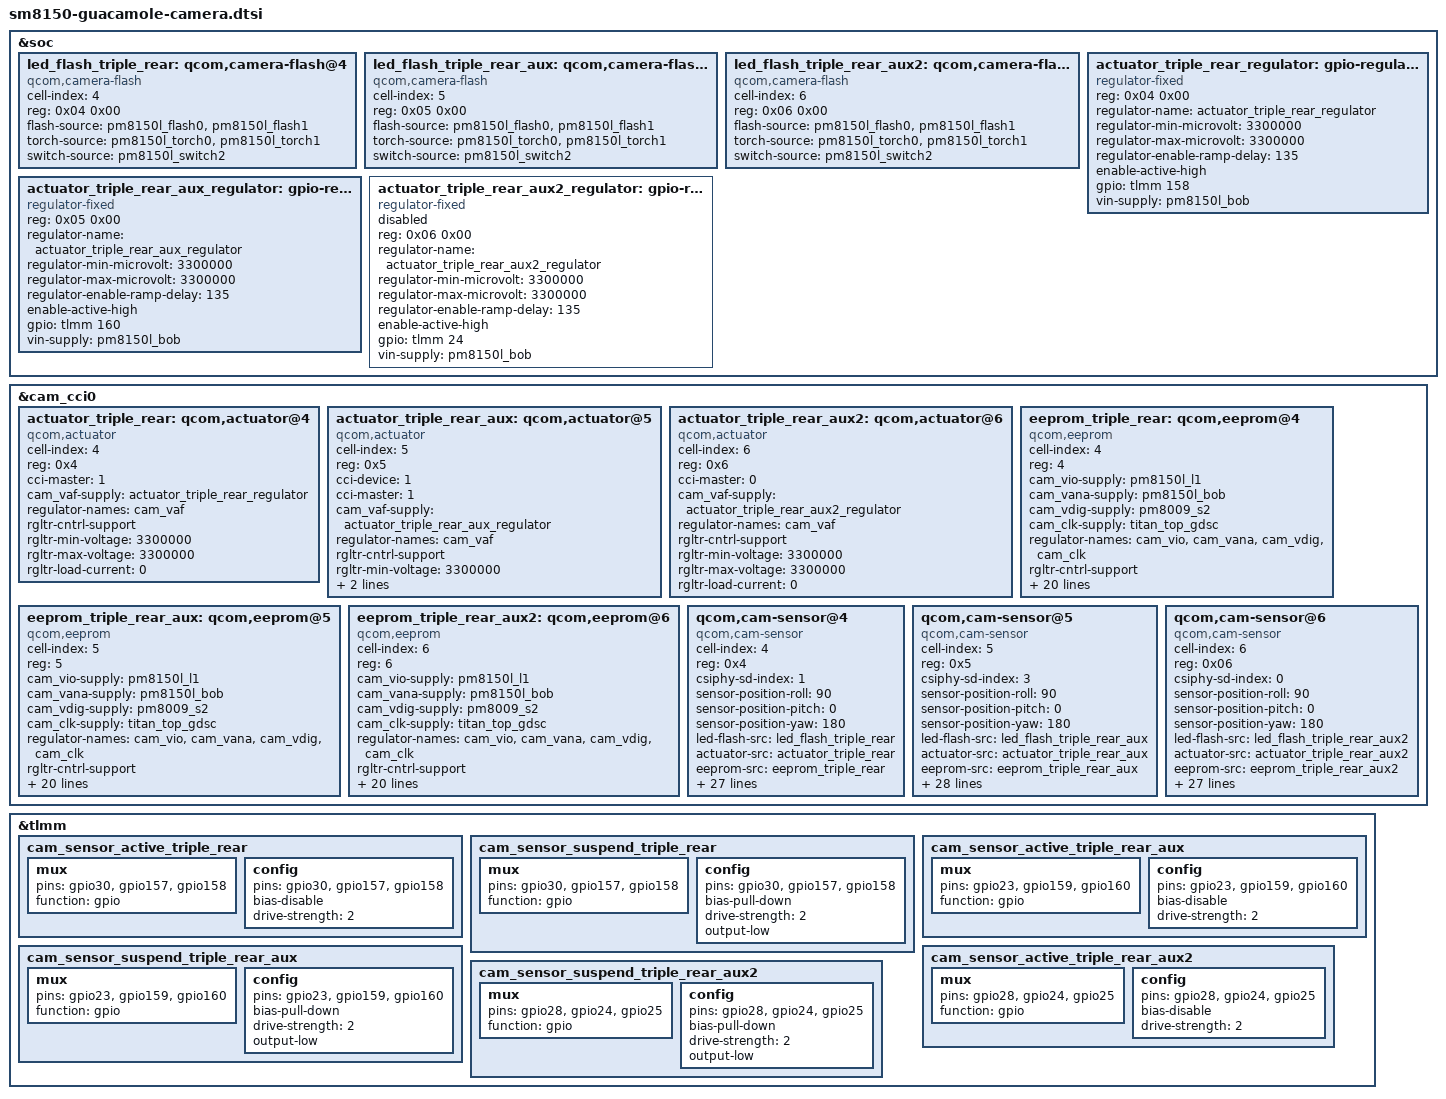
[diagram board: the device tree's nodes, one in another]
/*
 * Copyright (c) 2018, The Linux Foundation. All rights reserved.
 *
 * This program is free software; you can redistribute it and/or modify
 * it under the terms of the GNU General Public License version 2 and
 * only version 2 as published by the Free Software Foundation.
 *
 * This program is distributed in the hope that it will be useful,
 * but WITHOUT ANY WARRANTY; without even the implied warranty of
 * MERCHANTABILITY or FITNESS FOR A PARTICULAR PURPOSE.  See the
 * GNU General Public License for more details.
 */

&soc {
	led_flash_triple_rear: qcom,camera-flash@4 {
		cell-index = <4>;
		reg = <0x04 0x00>;
		compatible = "qcom,camera-flash";
		flash-source = <&pm8150l_flash0 &pm8150l_flash1>;
		torch-source = <&pm8150l_torch0 &pm8150l_torch1>;
		switch-source = <&pm8150l_switch2>;
		status = "ok";
	};

	led_flash_triple_rear_aux: qcom,camera-flash@5 {
		cell-index = <5>;
		reg = <0x05 0x00>;
		compatible = "qcom,camera-flash";
		flash-source = <&pm8150l_flash0 &pm8150l_flash1>;
		torch-source = <&pm8150l_torch0 &pm8150l_torch1>;
		switch-source = <&pm8150l_switch2>;
		status = "ok";
	};

	led_flash_triple_rear_aux2: qcom,camera-flash@6 {
		cell-index = <6>;
		reg = <0x06 0x00>;
		compatible = "qcom,camera-flash";
		flash-source = <&pm8150l_flash0 &pm8150l_flash1>;
		torch-source = <&pm8150l_torch0 &pm8150l_torch1>;
		switch-source = <&pm8150l_switch2>;
		status = "ok";
	};

	actuator_triple_rear_regulator: gpio-regulator@4 {
		compatible = "regulator-fixed";
		reg = <0x04 0x00>;
		regulator-name = "actuator_triple_rear_regulator";
		regulator-min-microvolt = <3300000>;
		regulator-max-microvolt = <3300000>;
		regulator-enable-ramp-delay = <135>;
		enable-active-high;
		gpio = <&tlmm 158 0>;
		vin-supply = <&pm8150l_bob>;
	};

	actuator_triple_rear_aux_regulator: gpio-regulator@5 {
		compatible = "regulator-fixed";
		reg = <0x05 0x00>;
		regulator-name = "actuator_triple_rear_aux_regulator";
		regulator-min-microvolt = <3300000>;
		regulator-max-microvolt = <3300000>;
		regulator-enable-ramp-delay = <135>;
		enable-active-high;
		gpio = <&tlmm 160 0>;
		vin-supply = <&pm8150l_bob>;
	};

	actuator_triple_rear_aux2_regulator: gpio-regulator@6 {
		compatible = "regulator-fixed";
		status = "disable";
		reg = <0x06 0x00>;
		regulator-name = "actuator_triple_rear_aux2_regulator";
		regulator-min-microvolt = <3300000>;
		regulator-max-microvolt = <3300000>;
		regulator-enable-ramp-delay = <135>;
		enable-active-high;
		gpio = <&tlmm 24 0>;
		vin-supply = <&pm8150l_bob>;
	};
};

&cam_cci0 {
	actuator_triple_rear: qcom,actuator@4 {
		cell-index = <4>;
		reg = <0x4>;
		compatible = "qcom,actuator";
		cci-master = <1>;
		cam_vaf-supply = <&actuator_triple_rear_regulator>;
		regulator-names = "cam_vaf";
		rgltr-cntrl-support;
		rgltr-min-voltage = <3300000>;
		rgltr-max-voltage = <3300000>;
		rgltr-load-current = <0>;
	};

	actuator_triple_rear_aux: qcom,actuator@5 {
		cell-index = <5>;
		reg = <0x5>;
		compatible = "qcom,actuator";
		cci-device = <1>;
		cci-master = <1>;
		cam_vaf-supply = <&actuator_triple_rear_aux_regulator>;
		regulator-names = "cam_vaf";
		rgltr-cntrl-support;
		rgltr-min-voltage = <3300000>;
		rgltr-max-voltage = <3300000>;
		rgltr-load-current = <0>;
	};

	actuator_triple_rear_aux2: qcom,actuator@6 {
		cell-index = <6>;
		reg = <0x6>;
		compatible = "qcom,actuator";
		cci-master = <0>;
		cam_vaf-supply = <&actuator_triple_rear_aux2_regulator>;
		regulator-names = "cam_vaf";
		rgltr-cntrl-support;
		rgltr-min-voltage = <3300000>;
		rgltr-max-voltage = <3300000>;
		rgltr-load-current = <0>;
	};

	eeprom_triple_rear: qcom,eeprom@4 {
		cell-index = <4>;
		reg = <4>;
		compatible = "qcom,eeprom";
		cam_vio-supply = <&pm8150l_l1>;
		cam_vana-supply = <&pm8150l_bob>;
		cam_vdig-supply = <&pm8009_s2>;
		cam_clk-supply = <&titan_top_gdsc>;
		regulator-names = "cam_vio", "cam_vana", "cam_vdig",
			"cam_clk";
		rgltr-cntrl-support;
		rgltr-min-voltage = <1800000 3008000 2856000 0>;
		rgltr-max-voltage = <1800000 4000000 3008000 0>;
		rgltr-load-current = <180000 2000000 519000 0>;
		gpio-no-mux = <0>;
		pinctrl-names = "cam_default", "cam_suspend";
		pinctrl-0 = <&cam_sensor_mclk1_active
				&cam_sensor_active_triple_rear>;
		pinctrl-1 = <&cam_sensor_mclk1_suspend
				&cam_sensor_suspend_triple_rear>;
		gpios = <&tlmm 14 0>,
			<&tlmm 30 0>,
			<&tlmm 157 0>;
		gpio-reset = <1>;
		gpio-vdig = <2>;
		gpio-req-tbl-num = <0 1 2>;
		gpio-req-tbl-flags = <1 0 0>;
		gpio-req-tbl-label = "CAMIF_MCLK1",
					"CAM_RESET4",
					"CAM_VDIG4";
		sensor-mode = <0>;
		cci-master = <1>;
		status = "ok";
		clocks = <&clock_camcc CAM_CC_MCLK1_CLK>;
		clock-names = "cam_clk";
		clock-cntl-level = "turbo";
		clock-rates = <24000000>;
	};

	eeprom_triple_rear_aux: qcom,eeprom@5 {
		cell-index = <5>;
		reg = <5>;
		compatible = "qcom,eeprom";
		cam_vio-supply = <&pm8150l_l1>;
		cam_vana-supply = <&pm8150l_bob>;
		cam_vdig-supply = <&pm8009_s2>;
		cam_clk-supply = <&titan_top_gdsc>;
		regulator-names = "cam_vio", "cam_vana", "cam_vdig",
			"cam_clk";
		rgltr-cntrl-support;
		rgltr-min-voltage = <1800000 3008000 2856000 0>;
		rgltr-max-voltage = <1800000 4000000 3008000 0>;
		rgltr-load-current = <180000 2000000 519000 0>;
		gpio-no-mux = <0>;
		pinctrl-names = "cam_default", "cam_suspend";
		pinctrl-0 = <&cam_sensor_mclk1_active
				&cam_sensor_active_triple_rear>;
		pinctrl-1 = <&cam_sensor_mclk1_suspend
				&cam_sensor_suspend_triple_rear>;
		gpios = <&tlmm 14 0>,
			<&tlmm 30 0>,
			<&tlmm 157 0>;
		gpio-reset = <1>;
		gpio-vdig = <2>;
		gpio-req-tbl-num = <0 1 2>;
		gpio-req-tbl-flags = <1 0 0>;
		gpio-req-tbl-label = "CAMIF_MCLK1",
					"CAM_RESET5",
					"CAM_VDIG5";
		sensor-mode = <0>;
		cci-master = <1>;
		status = "ok";
		clocks = <&clock_camcc CAM_CC_MCLK1_CLK>;
		clock-names = "cam_clk";
		clock-cntl-level = "turbo";
		clock-rates = <24000000>;
	};

	eeprom_triple_rear_aux2: qcom,eeprom@6 {
		cell-index = <6>;
		reg = <6>;
		compatible = "qcom,eeprom";
		cam_vio-supply = <&pm8150l_l1>;
		cam_vana-supply = <&pm8150l_bob>;
		cam_vdig-supply = <&pm8009_s2>;
		cam_clk-supply = <&titan_top_gdsc>;
		regulator-names = "cam_vio", "cam_vana", "cam_vdig",
			"cam_clk";
		rgltr-cntrl-support;
		rgltr-min-voltage = <1800000 3008000 2856000 0>;
		rgltr-max-voltage = <1800000 4000000 3008000 0>;
		rgltr-load-current = <180000 2000000 519000 0>;
		gpio-no-mux = <0>;
		pinctrl-names = "cam_default", "cam_suspend";
		pinctrl-0 = <&cam_sensor_mclk0_active
				&cam_sensor_active_triple_rear>;
		pinctrl-1 = <&cam_sensor_mclk0_suspend
				&cam_sensor_suspend_triple_rear>;
		gpios = <&tlmm 14 0>,
			<&tlmm 30 0>,
			<&tlmm 157 0>;
		gpio-reset = <1>;
		gpio-vdig = <2>;
		gpio-req-tbl-num = <0 1 2>;
		gpio-req-tbl-flags = <1 0 0>;
		gpio-req-tbl-label = "CAMIF_MCLK0",
					"CAM_RESET6",
					"CAM_VDIG6";
		sensor-mode = <0>;
		cci-master = <0>;
		status = "ok";
		clocks = <&clock_camcc CAM_CC_MCLK0_CLK>;
		clock-names = "cam_clk";
		clock-cntl-level = "turbo";
		clock-rates = <24000000>;
	};

	qcom,cam-sensor@4 {
		cell-index = <4>;
		compatible = "qcom,cam-sensor";
		reg = <0x4>;
		csiphy-sd-index = <1>;
		sensor-position-roll = <90>;
		sensor-position-pitch = <0>;
		sensor-position-yaw = <180>;
		led-flash-src = <&led_flash_triple_rear>;
		actuator-src = <&actuator_triple_rear>;
		eeprom-src = <&eeprom_triple_rear>;
		cam_vio-supply = <&pm8150l_l1>;
		cam_vana-supply = <&pm8150l_bob>;
		cam_vdig-supply = <&pm8009_s2>;
		cam_clk-supply = <&titan_top_gdsc>;
		regulator-names = "cam_vio", "cam_vana", "cam_vdig",
			"cam_clk";
		rgltr-cntrl-support;
		rgltr-min-voltage = <1800000 3008000 2856000 0>;
		rgltr-max-voltage = <1800000 4000000 3008000 0>;
		rgltr-load-current = <180000 2000000 519000 0>;
		gpio-no-mux = <0>;
		pinctrl-names = "cam_default", "cam_suspend";
		pinctrl-0 = <&cam_sensor_mclk1_active
				&cam_sensor_active_triple_rear>;
		pinctrl-1 = <&cam_sensor_mclk1_suspend
				&cam_sensor_suspend_triple_rear>;
		gpios = <&tlmm 14 0>,
			<&tlmm 30 0>,
			<&tlmm 157 0>;
		gpio-reset = <1>;
		gpio-vdig = <2>;
		gpio-req-tbl-num = <0 1 2>;
		gpio-req-tbl-flags = <1 0 0>;
		gpio-req-tbl-label = "CAMIF_MCLK1",
					"CAM_RESET4",
					"CAM_VDIG4";
		sensor-mode = <0>;
		cci-master = <1>;
		status = "ok";
		clocks = <&clock_camcc CAM_CC_MCLK1_CLK>;
		clock-names = "cam_clk";
		clock-cntl-level = "turbo";
		clock-rates = <24000000>;
	};

	qcom,cam-sensor@5 {
		cell-index = <5>;
		compatible = "qcom,cam-sensor";
		reg = <0x5>;
		csiphy-sd-index = <3>;
		sensor-position-roll = <90>;
		sensor-position-pitch = <0>;
		sensor-position-yaw = <180>;
		led-flash-src = <&led_flash_triple_rear_aux>;
		actuator-src = <&actuator_triple_rear_aux>;
		eeprom-src = <&eeprom_triple_rear_aux>;
		cam_vio-supply = <&pm8150l_l1>;
		cam_vana-supply = <&pm8150l_bob>;
		cam_vdig-supply = <&pm8009_s2>;
		cam_clk-supply = <&titan_top_gdsc>;
		regulator-names = "cam_vio", "cam_vana", "cam_vdig",
			"cam_clk";
		rgltr-cntrl-support;
		rgltr-min-voltage = <1800000 3008000 2856000 0>;
		rgltr-max-voltage = <1800000 4000000 3008000 0>;
		rgltr-load-current = <180000 2000000 519000 0>;
		gpio-no-mux = <0>;
		pinctrl-names = "cam_default", "cam_suspend";
		pinctrl-0 = <&cam_sensor_mclk3_active
				&cam_sensor_active_triple_rear_aux>;
		pinctrl-1 = <&cam_sensor_mclk3_suspend
				&cam_sensor_suspend_triple_rear_aux>;
		gpios = <&tlmm 16 0>,
			<&tlmm 23 0>,
			<&tlmm 159 0>;
		gpio-reset = <1>;
		gpio-vdig = <2>;
		gpio-req-tbl-num = <0 1 2>;
		gpio-req-tbl-flags = <1 0 0>;
		gpio-req-tbl-label = "CAMIF_MCLK3",
					"CAM_RESET5",
					"CAM_VDIG5";
		sensor-mode = <0>;
		cci-device = <1>;
		cci-master = <1>;
		status = "ok";
		clocks = <&clock_camcc CAM_CC_MCLK3_CLK>;
		clock-names = "cam_clk";
		clock-cntl-level = "turbo";
		clock-rates = <24000000>;
	};

	qcom,cam-sensor@6 {
		cell-index = <6>;
		compatible = "qcom,cam-sensor";
		reg = <0x06>;
		csiphy-sd-index = <0>;
		sensor-position-roll = <90>;
		sensor-position-pitch = <0>;
		sensor-position-yaw = <180>;
		led-flash-src = <&led_flash_triple_rear_aux2>;
		actuator-src = <&actuator_triple_rear_aux2>;
		eeprom-src = <&eeprom_triple_rear_aux2>;
		cam_vdig-supply = <&pm8009_s2>;
		cam_vio-supply = <&pm8150l_l1>;
		cam_vana-supply = <&pm8150l_bob>;
		cam_clk-supply = <&titan_top_gdsc>;
		regulator-names = "cam_vio", "cam_vana", "cam_vdig",
			"cam_clk";
		rgltr-cntrl-support;
		rgltr-min-voltage = <1800000 3008000 2856000 0>;
		rgltr-max-voltage = <1800000 4000000 3008000 0>;
		rgltr-load-current = <180000 2000000 519000 0>;
		gpio-no-mux = <0>;
		pinctrl-names = "cam_default", "cam_suspend";
		pinctrl-0 = <&cam_sensor_mclk0_active
				 &cam_sensor_active_triple_rear_aux2>;
		pinctrl-1 = <&cam_sensor_mclk0_suspend
				 &cam_sensor_suspend_triple_rear_aux2>;
		gpios = <&tlmm 13 0>,
			<&tlmm 28 0>,
			<&tlmm 25 0>;
		gpio-reset = <1>;
		gpio-vdig = <2>;
		gpio-req-tbl-num = <0 1 2>;
		gpio-req-tbl-flags = <1 0 0>;
		gpio-req-tbl-label = "CAMIF_MCLK0",
					"CAM_RESET6",
					"VDIG6";
		sensor-mode = <0>;
		cci-master = <0>;
		status = "ok";
		clocks = <&clock_camcc CAM_CC_MCLK0_CLK>;
		clock-names = "cam_clk";
		clock-cntl-level = "turbo";
		clock-rates = <24000000>;
	};
};

&tlmm {
	cam_sensor_active_triple_rear: cam_sensor_active_triple_rear {
		mux {
			pins = "gpio30", "gpio157", "gpio158";
			function = "gpio";
		};

		config {
			pins = "gpio30", "gpio157", "gpio158";
			bias-disable; /* No PULL */
			drive-strength = <2>; /* 2 MA */
		};
	};

	cam_sensor_suspend_triple_rear: cam_sensor_suspend_triple_rear {
		mux {
			pins = "gpio30", "gpio157", "gpio158";
			function = "gpio";
		};

		config {
			pins = "gpio30", "gpio157", "gpio158";
			bias-pull-down; /* PULL DOWN */
			drive-strength = <2>; /* 2 MA */
			output-low;
		};
	};

	cam_sensor_active_triple_rear_aux:
		cam_sensor_active_triple_rear_aux {
		mux {
			pins = "gpio23", "gpio159", "gpio160";
			function = "gpio";
		};

		config {
			pins = "gpio23", "gpio159", "gpio160";
			bias-disable; /* No PULL */
			drive-strength = <2>; /* 2 MA */
		};
	};

	cam_sensor_suspend_triple_rear_aux:
		cam_sensor_suspend_triple_rear_aux {
		mux {
			pins = "gpio23", "gpio159", "gpio160";
			function = "gpio";
		};

		config {
			pins = "gpio23", "gpio159", "gpio160";
			bias-pull-down; /* PULL DOWN */
			drive-strength = <2>; /* 2 MA */
			output-low;
		};
	};

	cam_sensor_active_triple_rear_aux2:
		cam_sensor_active_triple_rear_aux2 {
		mux {
			pins = "gpio28", "gpio24", "gpio25";
			function = "gpio";
		};

		config {
			pins = "gpio28", "gpio24", "gpio25";
			bias-disable; /* No PULL */
			drive-strength = <2>; /* 2 MA */
		};
	};

	cam_sensor_suspend_triple_rear_aux2:
		cam_sensor_suspend_triple_rear_aux2 {
		mux {
			pins = "gpio28", "gpio24", "gpio25";
			function = "gpio";
		};

		config {
			pins = "gpio28", "gpio24", "gpio25";
			bias-pull-down; /* PULL DOWN */
			drive-strength = <2>; /* 2 MA */
			output-low;
		};
	};
};
